# STM32WB30_CM4 register map
File version: 1.4-IAR
CPU: CM4 r0p1, little endian, MPU, FPU, 4 interrupt priority bits
Registers are 32-bit, read-write, reset 0x0 unless marked. A register's access mark holds for its fields unless they carry their own. Offsets are from the block's base; [hi:lo] are bit positions; lines under a group give offsets from that group; {n}, {i} and the like mark numbered series.

## ADC — Analog to Digital Converter instance 1
Base 0x50040000
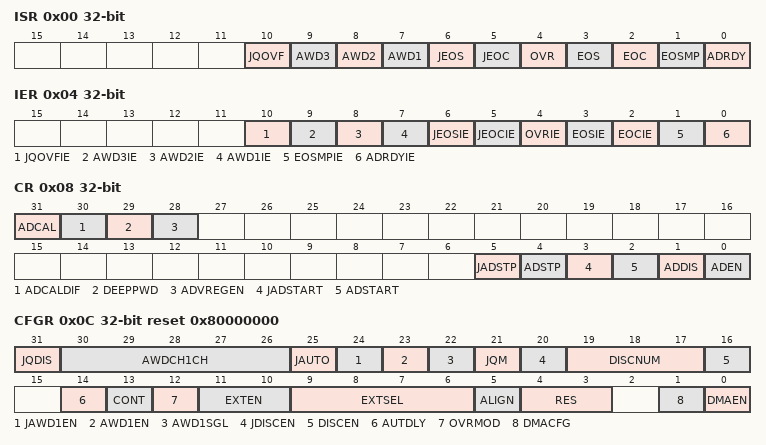
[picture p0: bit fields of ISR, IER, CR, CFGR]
0x00 ISR — ADC interrupt and status register
  [10] JQOVF — ADC group injected contexts queue overflow flag
  [9] AWD3 — ADC analog watchdog 3 flag
  [8] AWD2 — ADC analog watchdog 2 flag
  [7] AWD1 — ADC analog watchdog 1 flag
  [6] JEOS — ADC group injected end of sequence conversions flag
  [5] JEOC — ADC group injected end of unitary conversion flag
  [4] OVR — ADC group regular overrun flag
  [3] EOS — ADC group regular end of sequence conversions flag
  [2] EOC — ADC group regular end of unitary conversion flag
  [1] EOSMP — ADC group regular end of sampling flag
  [0] ADRDY — ADC ready flag
0x04 IER — ADC interrupt enable register
  [10] JQOVFIE — ADC group injected contexts queue overflow interrupt
  [9] AWD3IE — ADC analog watchdog 3 interrupt
  [8] AWD2IE — ADC analog watchdog 2 interrupt
  [7] AWD1IE — ADC analog watchdog 1 interrupt
  [6] JEOSIE — ADC group injected end of sequence conversions interrupt
  [5] JEOCIE — ADC group injected end of unitary conversion interrupt
  [4] OVRIE — ADC group regular overrun interrupt
  [3] EOSIE — ADC group regular end of sequence conversions interrupt
  [2] EOCIE — ADC group regular end of unitary conversion interrupt
  [1] EOSMPIE — ADC group regular end of sampling interrupt
  [0] ADRDYIE — ADC ready interrupt
0x08 CR — ADC control register
  [31] ADCAL — ADC calibration
  [30] ADCALDIF — ADC differential mode for calibration
  [29] DEEPPWD — ADC deep power down enable
  [28] ADVREGEN — ADC voltage regulator enable
  [5] JADSTP — ADC group injected conversion stop
  [4] ADSTP — ADC group regular conversion stop
  [3] JADSTART — ADC group injected conversion start
  [2] ADSTART — ADC group regular conversion start
  [1] ADDIS — ADC disable
  [0] ADEN — ADC enable
0x0C CFGR reset 0x80000000 — ADC configuration register 1
  [31] JQDIS — ADC group injected contexts queue disable
  [30:26] AWDCH1CH — ADC analog watchdog 1 monitored channel selection
  [25] JAUTO — ADC group injected automatic trigger mode
  [24] JAWD1EN — ADC analog watchdog 1 enable on scope ADC group injected
  [23] AWD1EN — ADC analog watchdog 1 enable on scope ADC group regular
  [22] AWD1SGL — ADC analog watchdog 1 monitoring a single channel or all channels
  [21] JQM — ADC group injected contexts queue mode
  [20] JDISCEN — ADC group injected sequencer discontinuous mode
  [19:17] DISCNUM — ADC group regular sequencer discontinuous number of ranks
  [16] DISCEN — ADC group regular sequencer discontinuous mode
  [14] AUTDLY — ADC low power auto wait
  [13] CONT — ADC group regular continuous conversion mode
  [12] OVRMOD — ADC group regular overrun configuration
  [11:10] EXTEN — ADC group regular external trigger polarity
  [9:6] EXTSEL — ADC group regular external trigger source
  [5] ALIGN — ADC data alignement
  [4:3] RES — ADC data resolution
  [1] DMACFG — ADC DMA transfer configuration
  [0] DMAEN — ADC DMA transfer enable
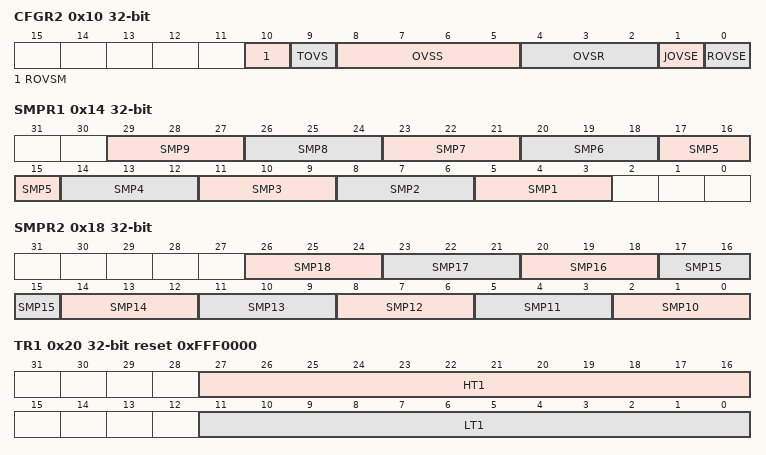
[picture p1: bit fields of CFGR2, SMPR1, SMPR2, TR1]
0x10 CFGR2 — ADC configuration register 2
  [10] ROVSM — ADC oversampling mode managing interlaced conversions of ADC group regular and group injected
  [9] TOVS — ADC oversampling discontinuous mode (triggered mode) for ADC group regular
  [8:5] OVSS — ADC oversampling shift
  [4:2] OVSR — ADC oversampling ratio
  [1] JOVSE — ADC oversampler enable on scope ADC group injected
  [0] ROVSE — ADC oversampler enable on scope ADC group regular
0x14 SMPR1 — ADC sampling time register 1
  [3n+2:3n] SMP{n} (n=1..9) — ADC channel {n} sampling time selection
0x18 SMPR2 — ADC sampling time register 2
  [3n-28:3n-30] SMP{n} (n=10..18) — ADC channel {n} sampling time selection
0x20 TR1 reset 0xFFF0000 — ADC analog watchdog 1 threshold register
  [27:16] HT1 — ADC analog watchdog 1 threshold high
  [11:0] LT1 — ADC analog watchdog 1 threshold low
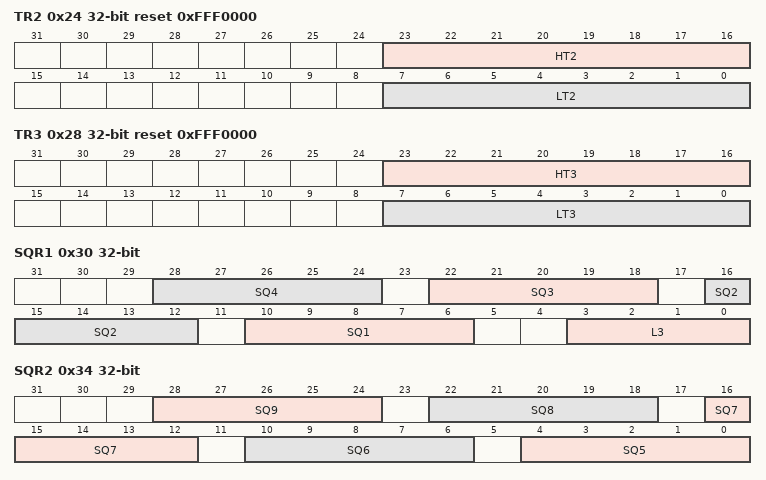
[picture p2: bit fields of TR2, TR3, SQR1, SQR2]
0x24 TR2 reset 0xFFF0000 — ADC analog watchdog 2 threshold register
  [23:16] HT2 — ADC analog watchdog 2 threshold high
  [7:0] LT2 — ADC analog watchdog 2 threshold low
0x28 TR3 reset 0xFFF0000 — ADC analog watchdog 3 threshold register
  [23:16] HT3 — ADC analog watchdog 3 threshold high
  [7:0] LT3 — ADC analog watchdog 3 threshold low
0x30 SQR1 — ADC group regular sequencer ranks register 1
  [6n+4:6n] SQ{n} (n=1..4) — ADC group regular sequencer rank {n}
  [3:0] L3
0x34 SQR2 — ADC group regular sequencer ranks register 2
  [6n-26:6n-30] SQ{n} (n=5..9) — ADC group regular sequencer rank {n}
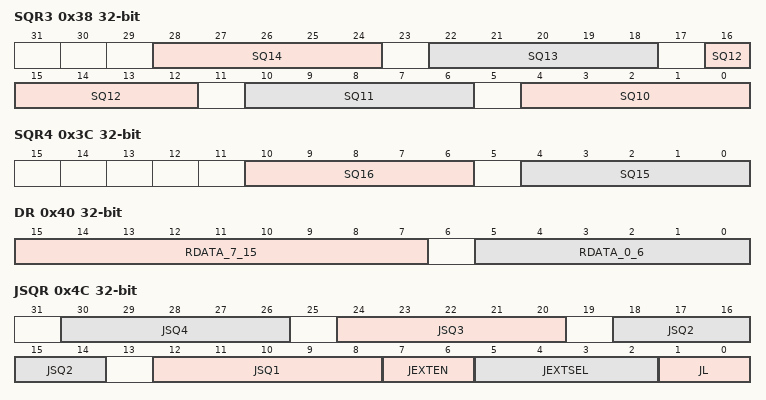
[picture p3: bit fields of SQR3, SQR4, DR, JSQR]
0x38 SQR3 — ADC group regular sequencer ranks register 3
  [6n-56:6n-60] SQ{n} (n=10..14) — ADC group regular sequencer rank {n}
0x3C SQR4 — ADC group regular sequencer ranks register 4
  [10:6] SQ16 — ADC group regular sequencer rank 16
  [4:0] SQ15 — ADC group regular sequencer rank 15
0x40 DR access per field — ADC group regular conversion data register
  [15:7] RDATA_7_15 ro — 15
  [5:0] RDATA_0_6 rw — Regular Data converted 0_6
0x4C JSQR — ADC group injected sequencer register
  [6n+6:6n+2] JSQ{n} (n=1..4) — ADC group injected sequencer rank {n}
  [7:6] JEXTEN — ADC group injected external trigger polarity
  [5:2] JEXTSEL — ADC group injected external trigger source
  [1:0] JL — ADC group injected sequencer scan length
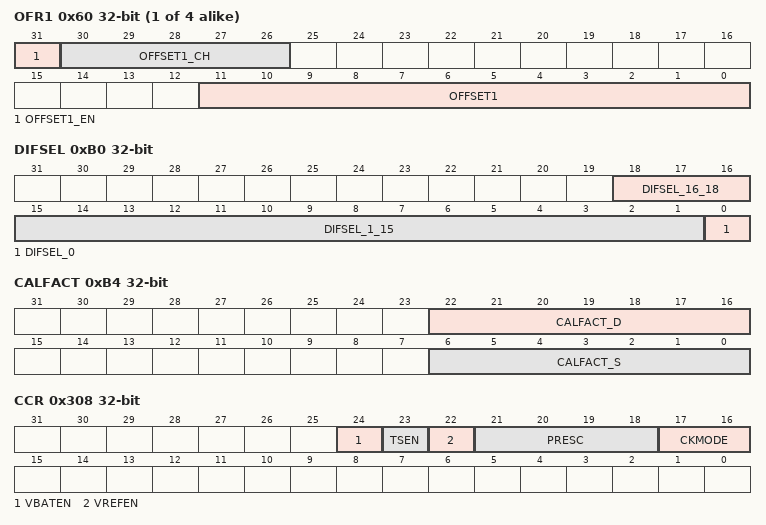
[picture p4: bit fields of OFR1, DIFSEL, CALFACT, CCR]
{0x5C+4i} OFR{i} (i=1..4) — ADC offset number {i} register
  [31] OFFSET{i}_EN — ADC offset number {i} enable
  [30:26] OFFSET{i}_CH — ADC offset number {i} channel selection
  [11:0] OFFSET{i} — ADC offset number {i} offset level
{0x7C+4i} JDR{i} ro (i=1..4) — ADC group injected sequencer rank {i} register
  [15:0] JDATA{i} — ADC group injected sequencer rank {i} conversion data
0xA0 AWD2CR — ADC analog watchdog 2 configuration register
  [18:0] AWD2CH — ADC analog watchdog 2 monitored channel selection
0xA4 AWD3CR — ADC analog watchdog 3 configuration register
  [18:0] AWD3CH — ADC analog watchdog 3 monitored channel selection
0xB0 DIFSEL access per field — ADC channel differential or single-ended mode selection register
  [18:16] DIFSEL_16_18 ro — ADC channel differential or single-ended mode for channels 18 to 16
  [15:1] DIFSEL_1_15 rw — ADC channel differential or single-ended mode for channels 1 to 15
  [0] DIFSEL_0 ro — ADC channel differential or single-ended mode for channel 0
0xB4 CALFACT — ADC calibration factors register
  [22:16] CALFACT_D — ADC calibration factor in differential mode
  [6:0] CALFACT_S — ADC calibration factor in single-ended mode
0x308 CCR — ADC common control register
  [24] VBATEN — VBAT enable
  [23] TSEN — Temperature sensor enable
  [22] VREFEN
  [21:18] PRESC — ADC prescaler
  [17:16] CKMODE — ADC clock mode

## Notices in the file
Copyright (c) 2020 STMicroelectronics.
SPDX-License-Identifier: Apache-2.0
Licensed under the Apache License, Version 2.0 (the "License");
you may not use this file except in compliance with the License.
You may obtain a copy of the License at
http://www.apache.org/licenses/LICENSE-2.0
Unless required by applicable law or agreed to in writing, software
distributed under the License is distributed on an "AS IS" BASIS,
WITHOUT WARRANTIES OR CONDITIONS OF ANY KIND, either express or implied.
See the License for the specific language governing permissions and
limitations under the License.
